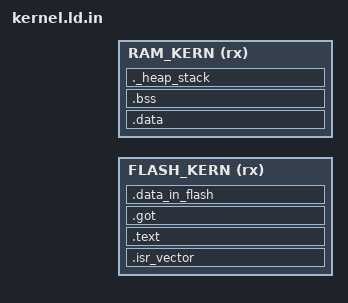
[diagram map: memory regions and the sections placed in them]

MEMORY
{
  /* sample flash, 512k */
  FLASH_KERN (rx) : ORIGIN = @ORIGIN_FLASH@, LENGTH = @LENGTH_FLASH@
  /* sample RAM, 256k */
  RAM_KERN   (rx) : ORIGIN = @ORIGIN_RAM@, LENGTH = @LENGTH_RAM@
}


_estack = _kern_init_msp_stack;

/* Define output sections */
SECTIONS
{
  /* The startup code goes first into FLASH */
  .isr_vector :
  {
    . = ALIGN(4);
    KEEP(*(.isr_vector)) /* Startup code */
    . = ALIGN(4);
  }>FLASH_KERN

  /* The program code and other data goes into FLASH */
  .text :
  {
    _stext = .;	            /* create a global symbol at data start */
    *startup*(.text.Reset_Handler)
    *(.text*)
    *(.rodata)         	/* .rodata sections (constants, strings, etc.) */
    *(.rodata*)         	/* .rodata sections (constants, strings, etc.) */
    *(.glue_7)         	/* glue arm to thumb code */
    *(.glue_7t)        	/* glue thumb to arm code */
	*(.eh_frame)

    KEEP (*(.init))
    KEEP (*(.fini))

    . = ALIGN(4);
    _etext = .;        	/* define a global symbols at end of code */
    _exit = .;

    _sigot = .;

  }>FLASH_KERN

  /* used by the startup to initialize got */
  .got : AT ( _sigot ) {
    . = ALIGN(4);
        _sgot = .;
        /*  *(.got.plt)
         *    We don't need plt segment
         *    since we do not need dynamic library relocation
         */
        *(.got)
        *(.got*)
    . = ALIGN(4);
    _egot = .;

  /* used by the startup to initialize data */
    _sidata = .;

  }>FLASH_KERN
  /* used by the startup to initialize data */
  /* Initialized data sections goes into RAM, load LMA copy after code */
  .data : AT ( _sidata )
  {
    . = ALIGN(4);
    _sdata = .;        /* create a global symbol at data start */
    *(.data)           /* .data sections */
    *(.data*)          /* .data* sections */
    _edata = .;        /* define a global symbol at data end */
  }>RAM_KERN

  .data_in_flash : AT ( _sidata )
  {
    /* to be sure that there is enough space in flash for .data, we fill the
     * content with .data size here. .data is added in a dedicated section
     * using the AT attribute
     * This section doesn't store anything but fullfill the flash with
     * the size of .data section */
    . = . + SIZEOF(.data);
    . = ALIGN(4);
  }>FLASH_KERN

  /* Uninitialized data section */
  . = ALIGN(4);
  .bss :
  {
    /* This is used by the startup in order to initialize the .bss section */
    _sbss = .;         /* define a global symbol at bss start */
    __bss_start__ = _sbss;
    *debug.o(.bss)
    *(.bss)
    *(.bss*)
    *(COMMON)

    . = ALIGN(4);
    _ebss = .;         /* define a global symbol at bss end */
    __bss_end__ = _ebss;
  }>RAM_KERN

    /* heap_stack section, used to check that there is enough RAM left */
  ._heap_stack :
  {
    . = ALIGN(4);
    PROVIDE ( end = . );
    PROVIDE ( _end = . );
    . = . + 4096; /* kernel idle thread stack */
    . = . + 4096; /* softirq thread stack */
    . = . + 4096; /* user ISR stack (remapped region) */
    . = . + 4096; /* kernel initial transient stack is not counted as it
                     is used only at early boot. We just give little space
                     to avoid .data+.bss collision with this stack at boot
                     time */
      _kern_init_msp_stack = .;
    . = ALIGN(4);
  }>RAM_KERN

  /* Remove information from the standard libraries */
  /DISCARD/ :
  {
    libgcc.a ( * )
  }

}
